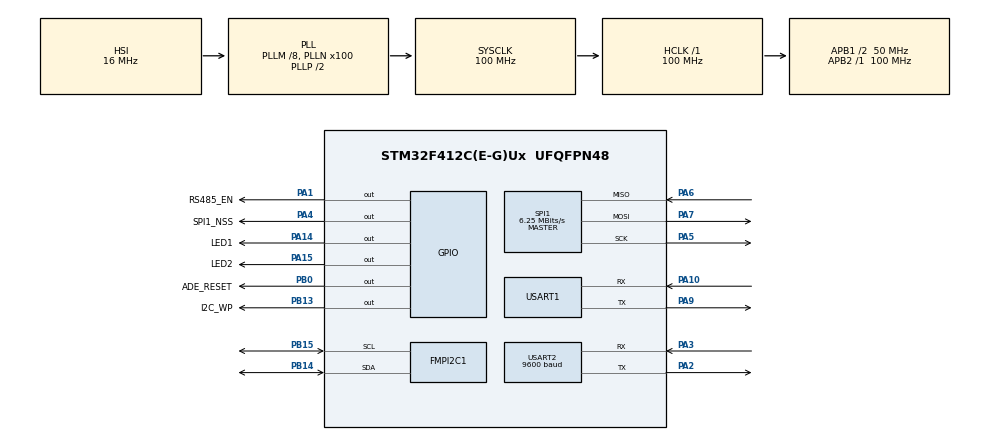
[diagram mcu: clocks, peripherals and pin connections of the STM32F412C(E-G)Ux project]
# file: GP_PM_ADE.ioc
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Dma.Request0=USART2_RX
Dma.Request1=USART2_TX
Dma.USART2_RX.0.Direction=DMA_PERIPH_TO_MEMORY
Dma.USART2_RX.0.FIFOMode=DMA_FIFOMODE_DISABLE
Dma.USART2_RX.0.Instance=DMA1_Stream5
Dma.USART2_RX.0.MemDataAlignment=DMA_MDATAALIGN_BYTE
Dma.USART2_RX.0.MemInc=DMA_MINC_ENABLE
Dma.USART2_RX.0.Mode=DMA_CIRCULAR
Dma.USART2_RX.0.PeriphDataAlignment=DMA_PDATAALIGN_BYTE
Dma.USART2_RX.0.PeriphInc=DMA_PINC_DISABLE
Dma.USART2_RX.0.Priority=DMA_PRIORITY_LOW
Dma.USART2_TX.1.Direction=DMA_MEMORY_TO_PERIPH
Dma.USART2_TX.1.FIFOMode=DMA_FIFOMODE_DISABLE
Dma.USART2_TX.1.Instance=DMA1_Stream6
Dma.USART2_TX.1.MemDataAlignment=DMA_MDATAALIGN_BYTE
Dma.USART2_TX.1.MemInc=DMA_MINC_ENABLE
Dma.USART2_TX.1.Mode=DMA_NORMAL
Dma.USART2_TX.1.PeriphDataAlignment=DMA_PDATAALIGN_BYTE
Dma.USART2_TX.1.PeriphInc=DMA_PINC_DISABLE
Dma.USART2_TX.1.Priority=DMA_PRIORITY_LOW
FMPI2C1.NoStretchMode=FMPI2C_NOSTRETCH_ENABLE
FMPI2C1.Timing=0x00C0EAFF
IWDG.Prescaler=IWDG_PRESCALER_32
Mcu.Family=STM32F4
Mcu.Name=STM32F412C(E-G)Ux
Mcu.Package=UFQFPN48
NVIC.DMA1_Stream5_IRQn=true\:0\:0\:false\:false\:true\:false\:true\:true
NVIC.DMA1_Stream6_IRQn=true\:0\:0\:false\:false\:true\:false\:true\:true
NVIC.PriorityGroup=NVIC_PRIORITYGROUP_4
NVIC.TIM3_IRQn=true\:0\:0\:false\:false\:true\:true\:true\:true
NVIC.TIM4_IRQn=true\:0\:0\:false\:false\:true\:true\:true\:true
NVIC.USART1_IRQn=true\:0\:0\:false\:false\:true\:true\:true\:true
NVIC.USART2_IRQn=true\:0\:0\:false\:false\:true\:true\:true\:true
PA1.GPIO_Label=RS485_EN
PA1.GPIO_PuPd=GPIO_PULLUP
PA1.GPIO_Speed=GPIO_SPEED_FREQ_HIGH
PA1.Signal=GPIO_Output
PA10.GPIO_PuPd=GPIO_PULLUP
PA10.Mode=Asynchronous
PA10.Signal=USART1_RX
PA14.GPIO_Label=LED1
PA14.Signal=GPIO_Output
PA15.GPIO_Label=LED2
PA15.Signal=GPIO_Output
PA2.Mode=Asynchronous
PA2.Signal=USART2_TX
PA3.Mode=Asynchronous
PA3.Signal=USART2_RX
PA4.GPIO_Label=SPI1_NSS
PA4.Signal=GPIO_Output
PA5.Mode=Full_Duplex_Master
PA5.Signal=SPI1_SCK
PA6.Mode=Full_Duplex_Master
PA6.Signal=SPI1_MISO
PA7.Mode=Full_Duplex_Master
PA7.Signal=SPI1_MOSI
PA9.GPIO_PuPd=GPIO_PULLUP
PA9.Mode=Asynchronous
PA9.Signal=USART1_TX
PB0.GPIO_Label=ADE_RESET
PB0.Signal=GPIO_Output
PB13.GPIO_Label=I2C_WP
PB13.GPIO_Speed=GPIO_SPEED_FREQ_MEDIUM
PB13.PinState=GPIO_PIN_RESET
PB13.Signal=GPIO_Output
PB14.Mode=I2C
PB14.Signal=FMPI2C1_SDA
PB15.Mode=I2C
PB15.Signal=FMPI2C1_SCL
ProjectManager.HeapSize=0x200
ProjectManager.StackSize=0x400
ProjectManager.TargetToolchain=STM32CubeIDE
RCC.AHBFreq_Value=100000000
RCC.APB1CLKDivider=RCC_HCLK_DIV2
RCC.APB1Freq_Value=50000000
RCC.APB1TimFreq_Value=100000000
RCC.APB2Freq_Value=100000000
RCC.APB2TimFreq_Value=100000000
RCC.CortexFreq_Value=100000000
RCC.HCLKFreq_Value=100000000
RCC.PLLM=8
RCC.PLLN=100
RCC.SYSCLKFreq_VALUE=100000000
RCC.SYSCLKSource=RCC_SYSCLKSOURCE_PLLCLK
RCC.USBFreq_Value=100000000
RCC.VCOOutputFreq_Value=200000000
SPI1.BaudRatePrescaler=SPI_BAUDRATEPRESCALER_16
SPI1.CLKPhase=SPI_PHASE_1EDGE
SPI1.CLKPolarity=SPI_POLARITY_LOW
SPI1.CalculateBaudRate=6.25 MBits/s
SPI1.DataSize=SPI_DATASIZE_16BIT
SPI1.Direction=SPI_DIRECTION_2LINES
SPI1.Mode=SPI_MODE_MASTER
SPI1.VirtualType=VM_MASTER
TIM3.Period=10000 - 1
TIM3.Prescaler=1-1
TIM4.Period=10000-1
TIM4.Prescaler=100-1
USART1.VirtualMode=VM_ASYNC
USART2.BaudRate=9600
USART2.VirtualMode=VM_ASYNC
VP_IWDG_VS_IWDG.Mode=IWDG_Activate
VP_TIM3_VS_ClockSourceINT.Mode=Internal
VP_TIM4_VS_ClockSourceINT.Mode=Internal
board=custom

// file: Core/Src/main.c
/* USER CODE BEGIN Header */
/**
  ******************************************************************************
  * @file           : main.c
  * @brief          : Main program body
  ******************************************************************************
  * @attention
  *
  * Copyright (c) 2025 STMicroelectronics.
  * All rights reserved.
  *
  * This software is licensed under terms that can be found in the LICENSE file
  * in the root directory of this software component.
  * If no LICENSE file comes with this software, it is provided AS-IS.
  *
  ******************************************************************************
  */
/* USER CODE END Header */
#include "main.h"
#include "dma.h"
#include "fmpi2c.h"
#include "iwdg.h"
#include "spi.h"
#include "tim.h"
#include "usart.h"
#include "gpio.h"

/* USER CODE BEGIN Includes */
#include "def.h"
/* USER CODE END Includes */

void SystemClock_Config(void);

int main(void)
{

  /* MCU Configuration--------------------------------------------------------*/

  /* Reset of all peripherals, Initializes the Flash interface and the Systick. */
  HAL_Init();

  /* Configure the system clock */
  SystemClock_Config();

  /* Initialize all configured peripherals */
  MX_GPIO_Init();
  MX_DMA_Init();
  MX_TIM3_Init();
  MX_USART1_UART_Init();
  MX_SPI1_Init();
  MX_FMPI2C1_Init();
  MX_USART2_UART_Init();
  MX_IWDG_Init();
  MX_TIM4_Init();
  /* USER CODE BEGIN 2 */
  GPInit();
  GPMain();
  /* USER CODE END 2 */

  /* Infinite loop */
  while (1)
  {

  }
}

void SystemClock_Config(void)
{
  RCC_OscInitTypeDef RCC_OscInitStruct = {0};
  RCC_ClkInitTypeDef RCC_ClkInitStruct = {0};

  /** Configure the main internal regulator output voltage
  */
  __HAL_RCC_PWR_CLK_ENABLE();
  __HAL_PWR_VOLTAGESCALING_CONFIG(PWR_REGULATOR_VOLTAGE_SCALE1);

  /** Initializes the RCC Oscillators according to the specified parameters
  * in the RCC_OscInitTypeDef structure.
  */
  RCC_OscInitStruct.OscillatorType = RCC_OSCILLATORTYPE_HSI|RCC_OSCILLATORTYPE_LSI;
  RCC_OscInitStruct.HSIState = RCC_HSI_ON;
  RCC_OscInitStruct.HSICalibrationValue = RCC_HSICALIBRATION_DEFAULT;
  RCC_OscInitStruct.LSIState = RCC_LSI_ON;
  RCC_OscInitStruct.PLL.PLLState = RCC_PLL_ON;
  RCC_OscInitStruct.PLL.PLLSource = RCC_PLLSOURCE_HSI;
  RCC_OscInitStruct.PLL.PLLM = 8;
  RCC_OscInitStruct.PLL.PLLN = 100;
  RCC_OscInitStruct.PLL.PLLP = RCC_PLLP_DIV2;
  RCC_OscInitStruct.PLL.PLLQ = 2;
  RCC_OscInitStruct.PLL.PLLR = 2;
  if (HAL_RCC_OscConfig(&RCC_OscInitStruct) != HAL_OK)
  {
    Error_Handler();
  }

  /** Initializes the CPU, AHB and APB buses clocks
  */
  RCC_ClkInitStruct.ClockType = RCC_CLOCKTYPE_HCLK|RCC_CLOCKTYPE_SYSCLK
                              |RCC_CLOCKTYPE_PCLK1|RCC_CLOCKTYPE_PCLK2;
  RCC_ClkInitStruct.SYSCLKSource = RCC_SYSCLKSOURCE_PLLCLK;
  RCC_ClkInitStruct.AHBCLKDivider = RCC_SYSCLK_DIV1;
  RCC_ClkInitStruct.APB1CLKDivider = RCC_HCLK_DIV2;
  RCC_ClkInitStruct.APB2CLKDivider = RCC_HCLK_DIV1;

  if (HAL_RCC_ClockConfig(&RCC_ClkInitStruct, FLASH_LATENCY_3) != HAL_OK)
  {
    Error_Handler();
  }
}

void Error_Handler(void)
{
  __disable_irq();
  while (1)
  {
  }
}
